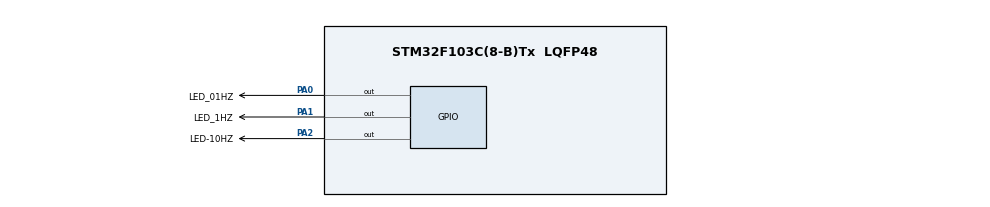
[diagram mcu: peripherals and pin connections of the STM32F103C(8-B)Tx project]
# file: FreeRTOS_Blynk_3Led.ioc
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FREERTOS.Tasks01=defaultTask,0,128,StartDefaultTask,Default,NULL,Dynamic,NULL,NULL
Mcu.Family=STM32F1
Mcu.Name=STM32F103C(8-B)Tx
Mcu.Package=LQFP48
NVIC.PriorityGroup=NVIC_PRIORITYGROUP_4
NVIC.TIM4_IRQn=true\:15\:0\:false\:false\:true\:false\:false\:true\:true
NVIC.TimeBase=TIM4_IRQn
NVIC.TimeBaseIP=TIM4
PA0-WKUP.GPIO_Label=LED_01HZ
PA0-WKUP.Signal=GPIO_Output
PA1.GPIO_Label=LED_1HZ
PA1.Signal=GPIO_Output
PA13.Mode=Serial_Wire
PA13.Signal=SYS_JTMS-SWDIO
PA14.Mode=Serial_Wire
PA14.Signal=SYS_JTCK-SWCLK
PA2.GPIO_Label=LED-10HZ
PA2.Signal=GPIO_Output
PD0-OSC_IN.Mode=HSE-External-Oscillator
PD0-OSC_IN.Signal=RCC_OSC_IN
PD1-OSC_OUT.Mode=HSE-External-Oscillator
PD1-OSC_OUT.Signal=RCC_OSC_OUT
ProjectManager.HeapSize=0x200
ProjectManager.StackSize=0x400
ProjectManager.TargetToolchain=MDK-ARM V5
RCC.APB1Freq_Value=8000000
RCC.APB2Freq_Value=8000000
VP_FREERTOS_VS_CMSIS_V1.Mode=CMSIS_V1
VP_SYS_VS_tim4.Mode=TIM4
board=custom

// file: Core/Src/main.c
/* USER CODE BEGIN Header */
/**
  ******************************************************************************
  * @file           : main.c
  * @brief          : Main program body
  ******************************************************************************
  * @attention
  *
  * Copyright (c) 2026 STMicroelectronics.
  * All rights reserved.
  *
  * This software is licensed under terms that can be found in the LICENSE file
  * in the root directory of this software component.
  * If no LICENSE file comes with this software, it is provided AS-IS.
  *
  ******************************************************************************
  */
/* USER CODE END Header */
#include "main.h"
#include "cmsis_os.h"

/* USER CODE BEGIN PTD */
typedef struct {
    GPIO_TypeDef* GPIOx;
    uint16_t GPIO_Pin;
    uint32_t ToggleHalfPeriodMs;
} LedConfig_t;
/* USER CODE END PTD */

osThreadId defaultTaskHandle;
/* USER CODE BEGIN PV */
LedConfig_t led1_config = {LED_01HZ_GPIO_Port, LED_01HZ_Pin, 5000};
LedConfig_t led2_config = {LED_1HZ_GPIO_Port,  LED_1HZ_Pin,  500};
LedConfig_t led3_config = {LED_10HZ_GPIO_Port, LED_10HZ_Pin, 50};
/* USER CODE END PV */

void SystemClock_Config(void);
static void MX_GPIO_Init(void);
void StartDefaultTask(void const * argument);

/* USER CODE BEGIN PFP */
void vLedTask(void *pvParameters);
/* USER CODE END PFP */

/* USER CODE BEGIN 4 */
/**
  * @brief Hàm Task chung di?u khi?n nh?p nháy LED d?a trên tham s? truy?n vào
  * @param pvParameters: Con tr? tr? t?i struct LedConfig_t
  */
void vLedTask(void *pvParameters)
{
    LedConfig_t *pLed = (LedConfig_t *)pvParameters;

    for (;;)
    {
        HAL_GPIO_TogglePin(pLed->GPIOx, pLed->GPIO_Pin);

        vTaskDelay(pdMS_TO_TICKS(pLed->ToggleHalfPeriodMs));
    }
}
/* USER CODE END 4 */

int main(void)
{

  /* MCU Configuration--------------------------------------------------------*/

  /* Reset of all peripherals, Initializes the Flash interface and the Systick. */
  HAL_Init();

  /* Configure the system clock */
  SystemClock_Config();

  /* Initialize all configured peripherals */
  MX_GPIO_Init();
  /* USER CODE BEGIN 2 */

  // T?o Task 1: Ði?u khi?n LED 0.1 Hz
  xTaskCreate(
      vLedTask,           // Hàm Callback c?a Task
      "LED_01Hz_Task",     // Tên Task (dùng d? debug)
      128,                // Dung lu?ng Stack (words)
      (void*)&led1_config,// Truy?n con tr? tham s? c?u hình LED 1
      osPriorityNormal,   // Ð? uu tiên
      NULL                // Task Handle (không dùng d?n)
  );

  // T?o Task 2: Ði?u khi?n LED 1 Hz
  xTaskCreate(
      vLedTask,
      "LED_1Hz_Task",
      128,
      (void*)&led2_config,
      osPriorityNormal,
      NULL
  );

  // T?o Task 3: Ði?u khi?n LED 10 Hz
  xTaskCreate(
      vLedTask,
      "LED_10Hz_Task",
      128,
      (void*)&led3_config,
      osPriorityNormal,
      NULL
  );

  /* USER CODE END 2 */

  /* Create the thread(s) */
  /* definition and creation of defaultTask */
  osThreadDef(defaultTask, StartDefaultTask, osPriorityNormal, 0, 128);
  defaultTaskHandle = osThreadCreate(osThread(defaultTask), NULL);

  /* Start scheduler */
  osKernelStart();

  /* We should never get here as control is now taken by the scheduler */

  /* Infinite loop */
  while (1)
  {

  }
}

void SystemClock_Config(void)
{
  RCC_OscInitTypeDef RCC_OscInitStruct = {0};
  RCC_ClkInitTypeDef RCC_ClkInitStruct = {0};

  /** Initializes the RCC Oscillators according to the specified parameters
  * in the RCC_OscInitTypeDef structure.
  */
  RCC_OscInitStruct.OscillatorType = RCC_OSCILLATORTYPE_HSI;
  RCC_OscInitStruct.HSIState = RCC_HSI_ON;
  RCC_OscInitStruct.HSICalibrationValue = RCC_HSICALIBRATION_DEFAULT;
  RCC_OscInitStruct.PLL.PLLState = RCC_PLL_NONE;
  if (HAL_RCC_OscConfig(&RCC_OscInitStruct) != HAL_OK)
  {
    Error_Handler();
  }

  /** Initializes the CPU, AHB and APB buses clocks
  */
  RCC_ClkInitStruct.ClockType = RCC_CLOCKTYPE_HCLK|RCC_CLOCKTYPE_SYSCLK
                              |RCC_CLOCKTYPE_PCLK1|RCC_CLOCKTYPE_PCLK2;
  RCC_ClkInitStruct.SYSCLKSource = RCC_SYSCLKSOURCE_HSI;
  RCC_ClkInitStruct.AHBCLKDivider = RCC_SYSCLK_DIV1;
  RCC_ClkInitStruct.APB1CLKDivider = RCC_HCLK_DIV1;
  RCC_ClkInitStruct.APB2CLKDivider = RCC_HCLK_DIV1;

  if (HAL_RCC_ClockConfig(&RCC_ClkInitStruct, FLASH_LATENCY_0) != HAL_OK)
  {
    Error_Handler();
  }
}

static void MX_GPIO_Init(void)
{
  GPIO_InitTypeDef GPIO_InitStruct = {0};

  /* GPIO Ports Clock Enable */
  __HAL_RCC_GPIOD_CLK_ENABLE();
  __HAL_RCC_GPIOA_CLK_ENABLE();

  /*Configure GPIO pin Output Level */
  HAL_GPIO_WritePin(GPIOA, LED_01HZ_Pin|LED_1HZ_Pin|LED_10HZ_Pin, GPIO_PIN_RESET);

  /*Configure GPIO pins : LED_01HZ_Pin LED_1HZ_Pin LED_10HZ_Pin */
  GPIO_InitStruct.Pin = LED_01HZ_Pin|LED_1HZ_Pin|LED_10HZ_Pin;
  GPIO_InitStruct.Mode = GPIO_MODE_OUTPUT_PP;
  GPIO_InitStruct.Pull = GPIO_NOPULL;
  GPIO_InitStruct.Speed = GPIO_SPEED_FREQ_LOW;
  HAL_GPIO_Init(GPIOA, &GPIO_InitStruct);

}

void StartDefaultTask(void const * argument)
{
  for(;;)
  {
    osDelay(1);
  }
}

void HAL_TIM_PeriodElapsedCallback(TIM_HandleTypeDef *htim)
{
  if (htim->Instance == TIM4)
  {
    HAL_IncTick();
  }
}

void Error_Handler(void)
{
  __disable_irq();
  while (1)
  {
  }
}
